AUTOSAR XML (schema 00047)
package /AppSwComponent_Dem/SwComponentType
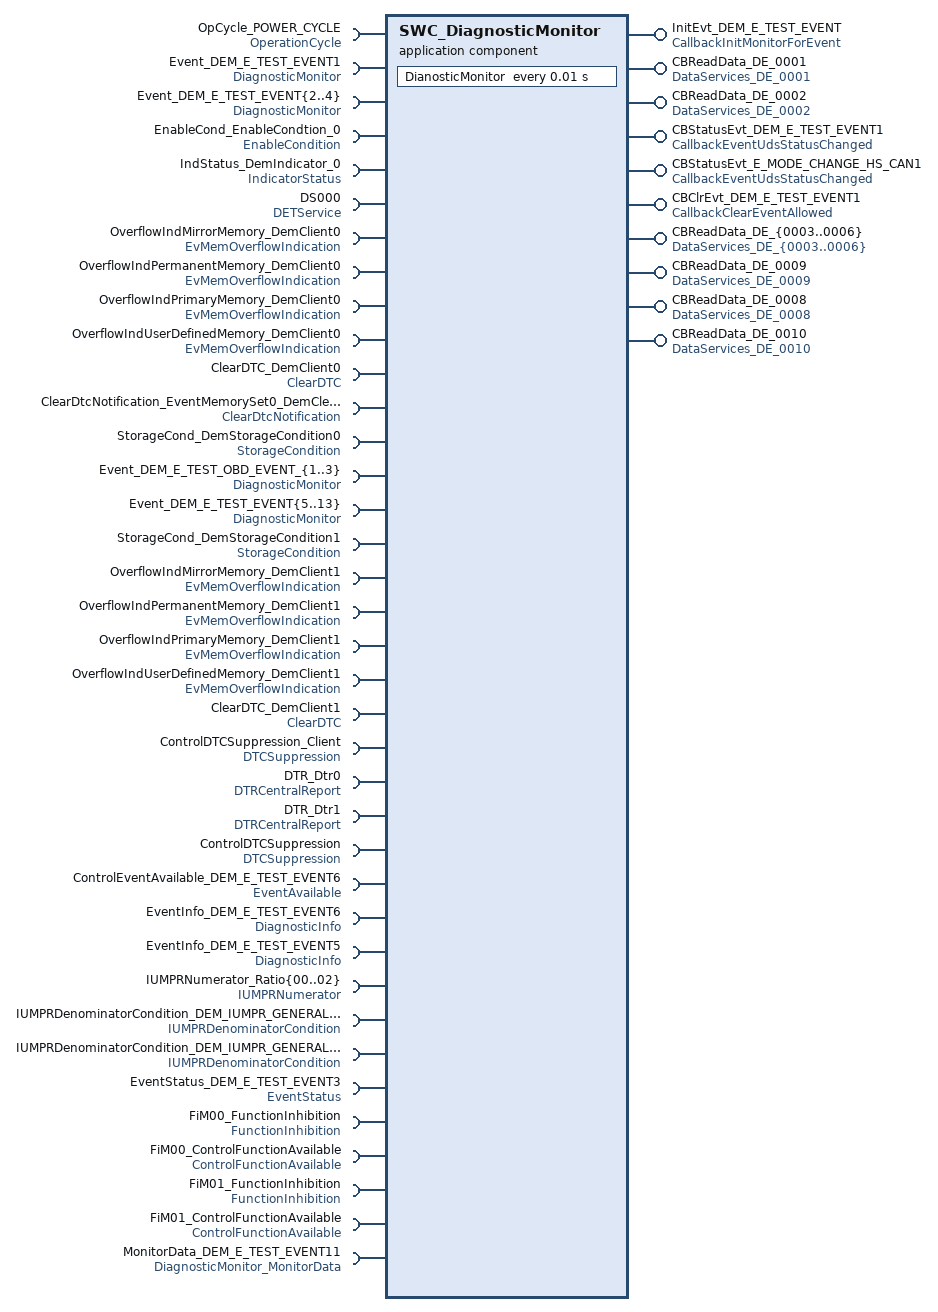
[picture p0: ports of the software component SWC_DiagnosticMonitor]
  application sw component type SWC_DiagnosticMonitor
    provide port InitEvt_DEM_E_TEST_EVENT: server-com-spec{operation=InitMonitorForEvent, queue-length=1}, provided-interface=CallbackInitMonitorForEvent
    require port OpCycle_POWER_CYCLE: client-com-spec=RestartOperationCycle, required-interface=OperationCycle
    require port Event_DEM_E_TEST_EVENT1: client-com-spec=SetEventStatus, required-interface=DiagnosticMonitor
    provide port CBReadData_DE_0001: server-com-spec{operation=ReadData, queue-length=1}, provided-interface=DataServices_DE_0001
    provide port CBReadData_DE_0002: server-com-spec{operation=ReadData, queue-length=1}, provided-interface=DataServices_DE_0002
    4 x require port:
      Event_DEM_E_TEST_EVENT{2..4}: client-com-spec=SetEventStatus, required-interface=DiagnosticMonitor
      EnableCond_EnableCondtion_0: client-com-spec=SetEnableCondition, required-interface=EnableCondition
    provide port CBStatusEvt_DEM_E_TEST_EVENT1: server-com-spec{operation=CallbackEventUdsStatusChanged, queue-length=1}, provided-interface=CallbackEventUdsStatusChanged
    require port IndStatus_DemIndicator_0: client-com-spec=GetIndicatorStatus, required-interface=IndicatorStatus
    require port DS000: required-com-specs=[ReportError, ReportRuntimeError], required-interface=DETService
    provide port CBStatusEvt_E_MODE_CHANGE_HS_CAN1: server-com-spec{operation=CallbackEventUdsStatusChanged, queue-length=1}, provided-interface=CallbackEventUdsStatusChanged
    provide port CBClrEvt_DEM_E_TEST_EVENT1: server-com-spec{operation=ClearEventAllowed, queue-length=1}, provided-interface=CallbackClearEventAllowed
    30 x require port:
      OverflowIndMirrorMemory_DemClient0: required-com-specs=[GetNumberOfEventMemoryEntries, GetEventMemoryOverflow], required-interface=EvMemOverflowIndication
      OverflowIndPermanentMemory_DemClient0: required-com-specs=[GetEventMemoryOverflow, GetNumberOfEventMemoryEntries], required-interface=EvMemOverflowIndication
      OverflowIndPrimaryMemory_DemClient0: required-com-specs=[GetEventMemoryOverflow, GetNumberOfEventMemoryEntries], required-interface=EvMemOverflowIndication
      OverflowIndUserDefinedMemory_DemClient0: required-com-specs=[GetEventMemoryOverflow, GetNumberOfEventMemoryEntries], required-interface=EvMemOverflowIndication
      ClearDTC_DemClient0: required-com-specs=[ClearDTC, SelectDTC], required-interface=ClearDTC
      ClearDtcNotification_EventMemorySet0_DemClearDTCNotification0: client-com-spec=ClearDtcNotification, required-interface=ClearDtcNotification
      StorageCond_DemStorageCondition0: client-com-spec=SetStorageCondition, required-interface=StorageCondition
      Event_DEM_E_TEST_OBD_EVENT_{1..3}: client-com-spec=SetEventStatus, required-interface=DiagnosticMonitor
      Event_DEM_E_TEST_EVENT{5..13}: client-com-spec=SetEventStatus, required-interface=DiagnosticMonitor
      StorageCond_DemStorageCondition1: client-com-spec=SetStorageCondition, required-interface=StorageCondition
      OverflowIndMirrorMemory_DemClient1: required-com-specs=[GetEventMemoryOverflow, GetNumberOfEventMemoryEntries], required-interface=EvMemOverflowIndication
      OverflowIndPermanentMemory_DemClient1: required-com-specs=[GetEventMemoryOverflow, GetNumberOfEventMemoryEntries], required-interface=EvMemOverflowIndication
      OverflowIndPrimaryMemory_DemClient1: required-com-specs=[GetEventMemoryOverflow, GetNumberOfEventMemoryEntries], required-interface=EvMemOverflowIndication
      OverflowIndUserDefinedMemory_DemClient1: required-com-specs=[GetEventMemoryOverflow, GetNumberOfEventMemoryEntries], required-interface=EvMemOverflowIndication
      ClearDTC_DemClient1: required-com-specs=[ClearDTC, SelectDTC], required-interface=ClearDTC
      ControlDTCSuppression_Client: required-com-specs=[GetDTCSuppression, SetDTCSuppression], required-interface=DTCSuppression
      DTR_Dtr0: client-com-spec=SetDTR, required-interface=DTRCentralReport
      DTR_Dtr1: client-com-spec=SetDTR, required-interface=DTRCentralReport
      ControlDTCSuppression: required-com-specs=[GetDTCSuppression, SetDTCSuppression], required-interface=DTCSuppression
      ControlEventAvailable_DEM_E_TEST_EVENT6: client-com-spec=SetEventAvailable, required-interface=EventAvailable
    4 x provide port, all with server-com-spec{operation=ReadData, queue-length=1}:
      CBReadData_DE_{0003..0006}: provided-interface=DataServices_DE_{0003..0006}
    12 x require port:
      EventInfo_DEM_E_TEST_EVENT6: client-com-spec=GetFaultDetectionCounter, required-interface=DiagnosticInfo
      EventInfo_DEM_E_TEST_EVENT5: required-com-specs=[GetEventFreezeFrameDataEx, GetEventExtendedDataRecordEx], required-interface=DiagnosticInfo
      IUMPRNumerator_Ratio{00..02}: client-com-spec=RepIUMPRFaultDetect, required-interface=IUMPRNumerator
      IUMPRDenominatorCondition_DEM_IUMPR_GENERAL_OBDCOND: client-com-spec=SetIUMPRDenCondition, required-interface=IUMPRDenominatorCondition
      IUMPRDenominatorCondition_DEM_IUMPR_GENERAL_INDIVIDUAL_DENOMINATOR: client-com-spec=SetIUMPRDenCondition, required-interface=IUMPRDenominatorCondition
      EventStatus_DEM_E_TEST_EVENT3: client-com-spec=SetWIRStatus, required-interface=EventStatus
      FiM00_FunctionInhibition: client-com-spec=GetFunctionPermission, required-interface=FunctionInhibition
      FiM00_ControlFunctionAvailable: client-com-spec=SetFunctionAvailable, required-interface=ControlFunctionAvailable
      FiM01_FunctionInhibition: client-com-spec=GetFunctionPermission, required-interface=FunctionInhibition
      FiM01_ControlFunctionAvailable: client-com-spec=SetFunctionAvailable, required-interface=ControlFunctionAvailable
    provide port CBReadData_DE_0009: server-com-spec{operation=ReadData, queue-length=1}, provided-interface=DataServices_DE_0009
    provide port CBReadData_DE_0008: server-com-spec{operation=ReadData, queue-length=1}, provided-interface=DataServices_DE_0008
    provide port CBReadData_DE_0010: server-com-spec{operation=ReadData, queue-length=1}, provided-interface=DataServices_DE_0010
    require port MonitorData_DEM_E_TEST_EVENT11: client-com-spec=SetEventStatusWithMonitorData, required-interface=DiagnosticMonitor_MonitorData
    behavior InternalBehaviors_DiagnosticMonitor: handle-termination-and-restart=NO-SUPPORT
      operation invoked event OIE_InitMonitorForEvent: start-on-event=InitMonitorForEvent_DEM_E_TEST, operation=InitEvt_DEM_E_TEST_EVENT.InitMonitorForEvent
      operation invoked event OIE_CBReadData_DE_0001: start-on-event=CBReadData_DE_0001, operation=CBReadData_DE_0001.ReadData
      operation invoked event OIE_CBReadData_DE_0002: start-on-event=CBReadData_DE_0002, operation=CBReadData_DE_0002.ReadData
      timing event TimingEvent_DiagnosticMonitor: start-on-event=DianosticMonitor, period=0.01
      10 x operation invoked event:
        OIE_CBStatusEvt_DEM_E_TEST_EVENT: start-on-event=CBStatusEvt_DEM_E_TEST_EVENT1, operation=CBStatusEvt_DEM_E_TEST_EVENT1.CallbackEventUdsStatusChanged
        OIE_CBStatusEvt_E_MODE_CHANGE_HS_CAN1_CBStatusEvt_E_MODE_CHANGE_HS_CAN1_EventStatusChanged: start-on-event=CBStatusEvt_E_MODE_CHANGE_HS_CAN1, operation=CBStatusEvt_E_MODE_CHANGE_HS_CAN1.CallbackEventUdsStatusChanged
        OIE_CBClrEvt_DEM_E_TEST_EVENT1: start-on-event=CBClrEvt_DEM_E_TEST_EVENT1, operation=CBClrEvt_DEM_E_TEST_EVENT1.ClearEventAllowed
        OIE_CBReadData_DE_{0003..0006}: start-on-event=CBReadData_DE_{0003..0006}, operation=CBReadData_DE_{0003..0006}.ReadData
        OIE_CBReadData_DE_0009: start-on-event=CBReadData_DE_0009, operation=CBReadData_DE_0009.ReadData
        OIE_CBReadData_DE_0008: start-on-event=CBReadData_DE_0008, operation=CBReadData_DE_0008.ReadData
        OIE_CBReadData_DE_0010: start-on-event=CBReadData_DE_0010, operation=CBReadData_DE_0010.ReadData
      15 x runnable, all with can-be-invoked-concurrently=true:
        InitMonitorForEvent_DEM_E_TEST
        CBReadData_DE_0001
        CBReadData_DE_0002
        DianosticMonitor: symbol=DiagnosticMonitor
          60 x sync call:
            SSCP_SetOperationCycleState: operation=OpCycle_POWER_CYCLE.RestartOperationCycle
            DEM_E_TEST_EVENT{1..4}_SetEventStatus: operation=Event_DEM_E_TEST_EVENT{1..4}.SetEventStatus
            EnableCond_EnableCondition_0: operation=EnableCond_EnableCondtion_0.SetEnableCondition
            IndStatus_DemIndicator_0: operation=IndStatus_DemIndicator_0.GetIndicatorStatus
            Det_ReportError_DS000: operation=DS000.ReportError
            ReportRuntimeError_DS000: operation=DS000.ReportRuntimeError
            SSCP_ClearDtcNotification_EventMemorySet0_DemClearDTCNotification0: operation=ClearDtcNotification_EventMemorySet0_DemClearDTCNotification0.ClearDtcNotification
            SSCP_StorageCond_DemStorageCondition0: operation=StorageCond_DemStorageCondition0.SetStorageCondition
            SSCP_OverflowIndMirrorMemory_DemClient0_GetEventMemoryOverflow: operation=OverflowIndMirrorMemory_DemClient0.GetEventMemoryOverflow
            SSCP_OverflowIndMirrorMemory_DemClient0_GetNumberOfEventMemoryEntries: operation=OverflowIndMirrorMemory_DemClient0.GetNumberOfEventMemoryEntries
            SSCP_OverflowIndPermanentMemory_DemClient0_GetEventMemoryOverflow: operation=OverflowIndPermanentMemory_DemClient0.GetEventMemoryOverflow
            SSCP_OverflowIndPermanentMemory_DemClient0_GetNumberOfEventMemoryEntries: operation=OverflowIndPermanentMemory_DemClient0.GetNumberOfEventMemoryEntries
            SSCP_OverflowIndPrimaryMemory_DemClient0_GetEventMemoryOverflow: operation=OverflowIndPrimaryMemory_DemClient0.GetEventMemoryOverflow
            SSCP_OverflowIndPrimaryMemory_DemClient0_GetNumberOfEventMemoryEntries: operation=OverflowIndPrimaryMemory_DemClient0.GetNumberOfEventMemoryEntries
            Event_DEM_E_TEST_OBD_EVENT_{1..3}_SetEventStatus: operation=Event_DEM_E_TEST_OBD_EVENT_{1..3}.SetEventStatus
            SSCP_DEM_E_TEST_EVENT{7..13}_SetEventStatus: operation=Event_DEM_E_TEST_EVENT{7..13}.SetEventStatus
            SSCP_StorageCon0_SetStorageCondition: operation=StorageCond_DemStorageCondition1.SetStorageCondition
            SSCP_Client0_SelectDTC: operation=ClearDTC_DemClient0.SelectDTC
            SSCP_Client0_ClearDTC: operation=ClearDTC_DemClient0.ClearDTC
            SSCP_OverflowIndMirrorMemory_DemClient1_GetEventMemoryOverflow: operation=OverflowIndMirrorMemory_DemClient1.GetEventMemoryOverflow
            SSCP_OverflowIndMirrorMemory_DemClient1_GetNumberOfEventMemoryEntries: operation=OverflowIndMirrorMemory_DemClient1.GetNumberOfEventMemoryEntries
            SSCP_OverflowIndPermanentMemory_DemClient1_GetEventMemoryOverflow: operation=OverflowIndPermanentMemory_DemClient1.GetEventMemoryOverflow
            SSCP_OverflowIndPermanentMemory_DemClient1_GetNumberOfEventMemoryEntries: operation=OverflowIndPermanentMemory_DemClient1.GetNumberOfEventMemoryEntries
            SSCP_OverflowIndPrimaryMemory_DemClient1_GetEventMemoryOverflow: operation=OverflowIndPrimaryMemory_DemClient1.GetEventMemoryOverflow
            SSCP_OverflowIndPrimaryMemory_DemClient1_GetNumberOfEventMemoryEntries: operation=OverflowIndPrimaryMemory_DemClient1.GetNumberOfEventMemoryEntries
            SSCP_DEM_E_TEST_EVENT6_SetEventStatus: operation=Event_DEM_E_TEST_EVENT6.SetEventStatus
            SSCP_DEM_E_TEST_EVENT5_SetEventStatus: operation=Event_DEM_E_TEST_EVENT5.SetEventStatus
            SSCP_Client1_SelectDTC: operation=ClearDTC_DemClient1.SelectDTC
            SSCP_Client1_ClearDTC: operation=ClearDTC_DemClient1.ClearDTC
            SSCP_Dtr_Dtr0: operation=DTR_Dtr0.SetDTR
            SSCP_Dtr_Dtr1: operation=DTR_Dtr1.SetDTR
            SSCP_ControlDTCSuppression_GetDtcSuppression: operation=ControlDTCSuppression.GetDTCSuppression
            SSCP_ControlDTCSuppression_SetDtcSuppression: operation=ControlDTCSuppression.SetDTCSuppression
            SSCP_ControlEventAvailable_SetEventAvailable_DEM_E_TEST_EVENT1: operation=ControlEventAvailable_DEM_E_TEST_EVENT6.SetEventAvailable
            SSCP_DEM_E_TEST_EVENT6_GetFaultDetectionCounter: operation=EventInfo_DEM_E_TEST_EVENT6.GetFaultDetectionCounter
            SSCP_IUMPRNumerator_Ratio00: operation=IUMPRNumerator_Ratio00.RepIUMPRFaultDetect
            SSCP_IUMPRNumerator_Ratio01: operation=IUMPRNumerator_Ratio01.RepIUMPRFaultDetect
            SSCP_IUMPRNumerator_02: operation=IUMPRNumerator_Ratio02.RepIUMPRFaultDetect
            SSCP_IUMPRDenominatorCondition_DEM_IUMPR_GENERAL_OBDCOND: operation=IUMPRDenominatorCondition_DEM_IUMPR_GENERAL_OBDCOND.SetIUMPRDenCondition
            SSCP_IUMPRDenominatorCondition_DEM_IUMPR_GENERAL_INDIVIDUAL_DENOMINATOR: operation=IUMPRDenominatorCondition_DEM_IUMPR_GENERAL_INDIVIDUAL_DENOMINATOR.SetIUMPRDenCondition
            SSCP_EventInfo_DEM_E_TEST_EVENT5_GetEventFreezeFrameDataEx: operation=EventInfo_DEM_E_TEST_EVENT5.GetEventExtendedDataRecordEx
            SSCP_EventInfo_DEM_E_TEST_EVENT5_GetEventExtendedDataRecordEx: operation=EventInfo_DEM_E_TEST_EVENT5.GetEventFreezeFrameDataEx
            SSCP_EventStatus_DEM_E_TEST_EVENT3_SetWIRStatus: operation=EventStatus_DEM_E_TEST_EVENT3.SetWIRStatus
            SSCP_OverflowIndUserDefined_DemClient1_GetEventMemoryOverflow: operation=OverflowIndUserDefinedMemory_DemClient1.GetNumberOfEventMemoryEntries
            SSCP_FiM00_FunctionInhibition_GetFunctionPermission: operation=FiM00_FunctionInhibition.GetFunctionPermission
            SSCP_FiM00_ControlFunctionAvailable_SetFunctionAvailable: operation=FiM00_ControlFunctionAvailable.SetFunctionAvailable
            SSCP_FiM01_FunctionInhibition_GetFunctionPermission: operation=FiM01_FunctionInhibition.GetFunctionPermission
            SSCP_FiM01_ControlFunctionAvailable_SetFunctionAvailable: operation=FiM01_ControlFunctionAvailable.SetFunctionAvailable
            SSCP_SetEventStatusWithMonitorData: operation=MonitorData_DEM_E_TEST_EVENT11.SetEventStatusWithMonitorData
        CBStatusEvt_DEM_E_TEST_EVENT1
        CBStatusEvt_E_MODE_CHANGE_HS_CAN1
        CBClrEvt_DEM_E_TEST_EVENT1
        ClearDtcNotification_EventMemorySet0_DemClearDTCNotification0
        CBReadData_DE_{0003..0006}
        CBReadData_DE_{0008..0010}
  swc implementation SWC_DiagnosticMonitor_Implementation: behavior=InternalBehaviors_DiagnosticMonitor
    code-descriptors:
      code Default
